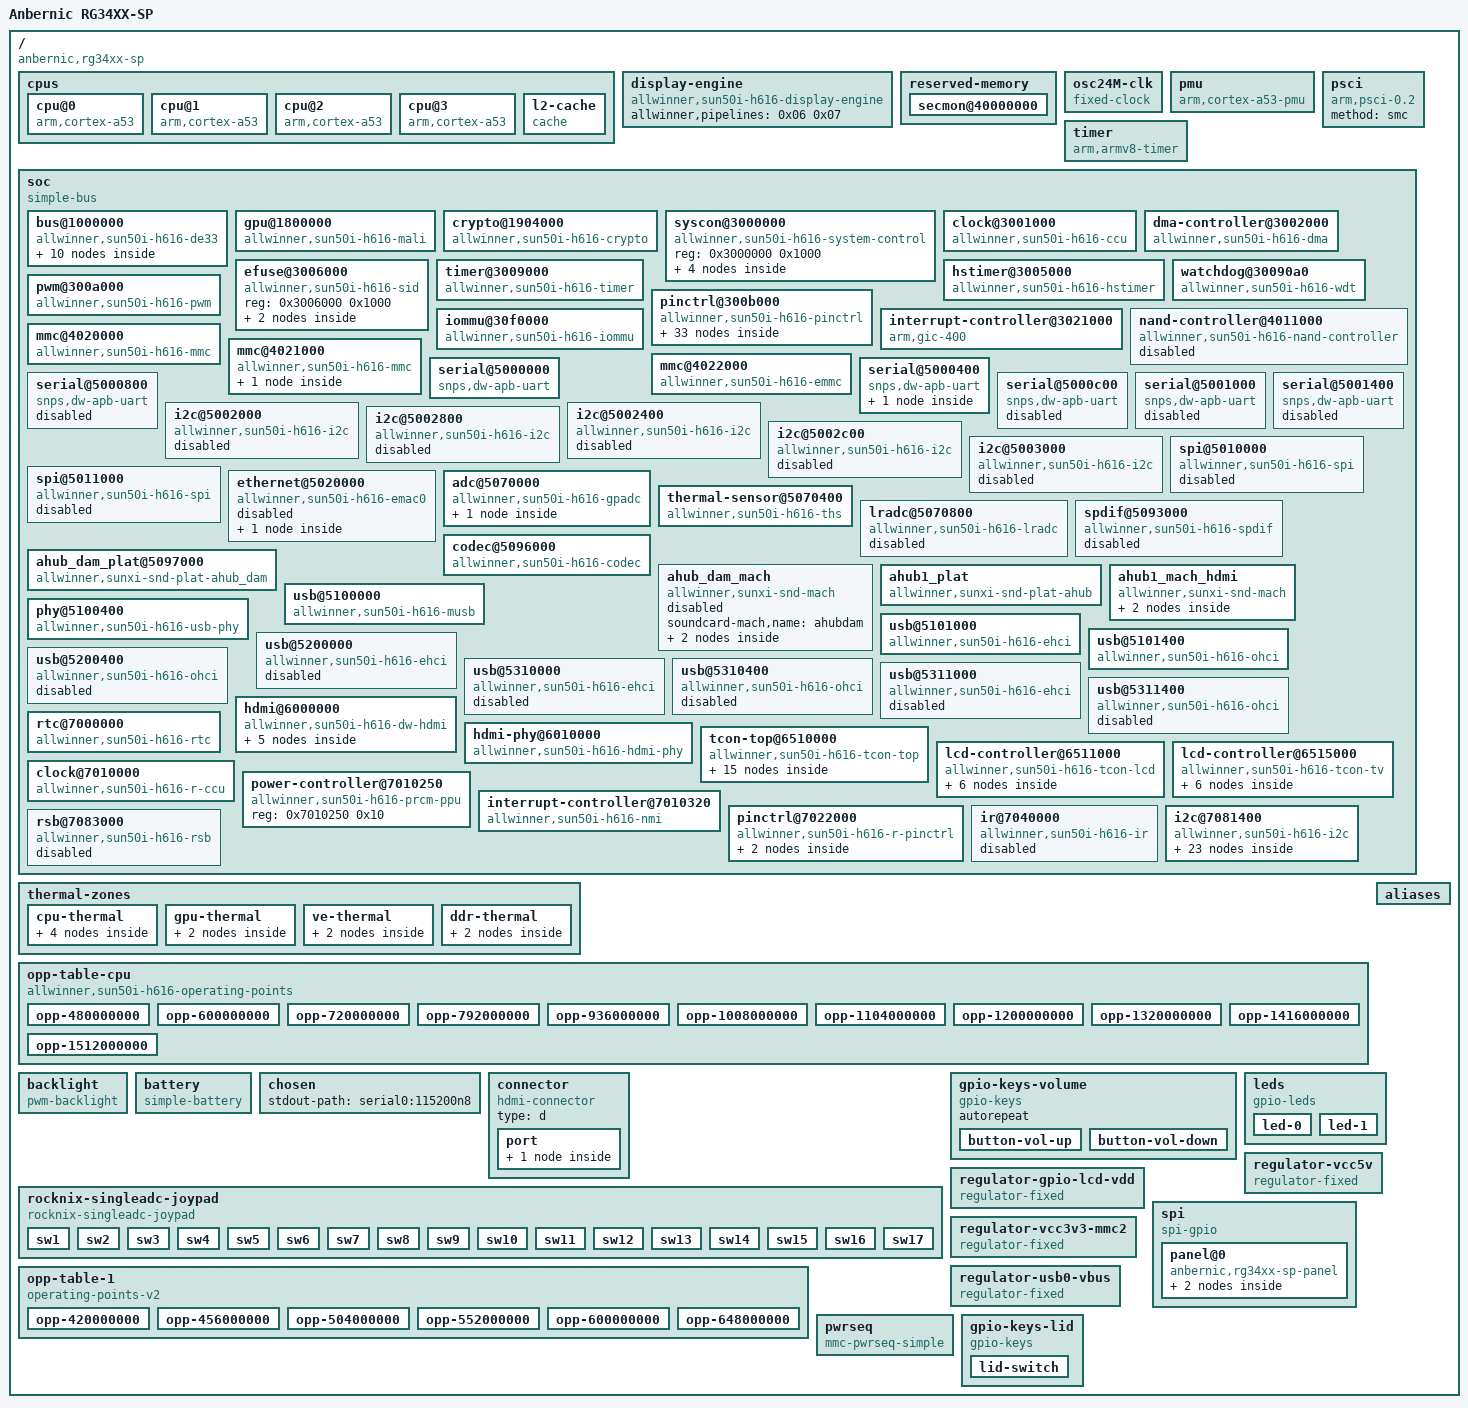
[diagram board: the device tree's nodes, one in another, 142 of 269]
/dts-v1/;

/ {
	interrupt-parent = <0x01>;
	#address-cells = <0x02>;
	#size-cells = <0x02>;
	model = "Anbernic RG34XX-SP";
	chassis-type = "handset";
	compatible = "anbernic,rg34xx-sp\0allwinner,sun50i-h700";
	rocknix-dt-id = "sun50i-h700-anbernic-rg34xx-sp";

	cpus {
		#address-cells = <0x01>;
		#size-cells = <0x00>;

		cpu@0 {
			compatible = "arm,cortex-a53";
			device_type = "cpu";
			reg = <0x00>;
			enable-method = "psci";
			clocks = <0x02 0x15>;
			#cooling-cells = <0x02>;
			i-cache-size = <0x8000>;
			i-cache-line-size = <0x40>;
			i-cache-sets = <0x100>;
			d-cache-size = <0x8000>;
			d-cache-line-size = <0x40>;
			d-cache-sets = <0x80>;
			next-level-cache = <0x03>;
			operating-points-v2 = <0x04>;
			cpu-supply = <0x05>;
			phandle = <0x08>;
		};

		cpu@1 {
			compatible = "arm,cortex-a53";
			device_type = "cpu";
			reg = <0x01>;
			enable-method = "psci";
			clocks = <0x02 0x15>;
			#cooling-cells = <0x02>;
			i-cache-size = <0x8000>;
			i-cache-line-size = <0x40>;
			i-cache-sets = <0x100>;
			d-cache-size = <0x8000>;
			d-cache-line-size = <0x40>;
			d-cache-sets = <0x80>;
			next-level-cache = <0x03>;
			operating-points-v2 = <0x04>;
			phandle = <0x09>;
		};

		cpu@2 {
			compatible = "arm,cortex-a53";
			device_type = "cpu";
			reg = <0x02>;
			enable-method = "psci";
			clocks = <0x02 0x15>;
			#cooling-cells = <0x02>;
			i-cache-size = <0x8000>;
			i-cache-line-size = <0x40>;
			i-cache-sets = <0x100>;
			d-cache-size = <0x8000>;
			d-cache-line-size = <0x40>;
			d-cache-sets = <0x80>;
			next-level-cache = <0x03>;
			operating-points-v2 = <0x04>;
			phandle = <0x0a>;
		};

		cpu@3 {
			compatible = "arm,cortex-a53";
			device_type = "cpu";
			reg = <0x03>;
			enable-method = "psci";
			clocks = <0x02 0x15>;
			#cooling-cells = <0x02>;
			i-cache-size = <0x8000>;
			i-cache-line-size = <0x40>;
			i-cache-sets = <0x100>;
			d-cache-size = <0x8000>;
			d-cache-line-size = <0x40>;
			d-cache-sets = <0x80>;
			next-level-cache = <0x03>;
			operating-points-v2 = <0x04>;
			phandle = <0x0b>;
		};

		l2-cache {
			compatible = "cache";
			cache-level = <0x02>;
			cache-unified;
			cache-size = <0x40000>;
			cache-line-size = <0x40>;
			cache-sets = <0x100>;
			phandle = <0x03>;
		};
	};

	display-engine {
		compatible = "allwinner,sun50i-h616-display-engine";
		allwinner,pipelines = <0x06 0x07>;
		status = "okay";
		phandle = <0x57>;
	};

	reserved-memory {
		#address-cells = <0x02>;
		#size-cells = <0x02>;
		ranges;

		secmon@40000000 {
			reg = <0x00 0x40000000 0x00 0x40000>;
			no-map;
		};
	};

	osc24M-clk {
		#clock-cells = <0x00>;
		compatible = "fixed-clock";
		clock-frequency = <0x16e3600>;
		clock-output-names = "osc24M";
		phandle = <0x15>;
	};

	pmu {
		compatible = "arm,cortex-a53-pmu";
		interrupts = <0x00 0x8c 0x04 0x00 0x8d 0x04 0x00 0x8e 0x04 0x00 0x8f 0x04>;
		interrupt-affinity = <0x08 0x09 0x0a 0x0b>;
	};

	psci {
		compatible = "arm,psci-0.2";
		method = "smc";
	};

	timer {
		compatible = "arm,armv8-timer";
		arm,no-tick-in-suspend;
		interrupts = <0x01 0x0d 0xf04 0x01 0x0e 0xf04 0x01 0x0b 0xf04 0x01 0x0a 0xf04>;
	};

	soc {
		compatible = "simple-bus";
		#address-cells = <0x01>;
		#size-cells = <0x01>;
		ranges = <0x00 0x00 0x00 0x40000000>;

		bus@1000000 {
			compatible = "allwinner,sun50i-h616-de33\0allwinner,sun50i-a64-de2";
			reg = <0x1000000 0x400000>;
			allwinner,sram = <0x0c 0x01>;
			#address-cells = <0x01>;
			#size-cells = <0x01>;
			ranges = <0x00 0x1000000 0x400000>;

			clock@8000 {
				compatible = "allwinner,sun50i-h616-de33-clk";
				reg = <0x8000 0x100>;
				clocks = <0x02 0x1d 0x02 0x1e>;
				clock-names = "mod\0bus";
				resets = <0x02 0x01>;
				#clock-cells = <0x01>;
				#reset-cells = <0x01>;
				phandle = <0x0d>;
			};

			planes@100000 {
				compatible = "allwinner,sun50i-h616-de33-planes";
				reg = <0x100000 0x180000>;
				allwinner,plane-mapping = <0x0d>;
				phandle = <0x0e>;
			};

			mixer@280000 {
				compatible = "allwinner,sun50i-h616-de33-mixer-0";
				reg = <0x280000 0x20000 0x8100 0x40>;
				clocks = <0x0d 0x00 0x0d 0x06>;
				clock-names = "bus\0mod";
				resets = <0x0d 0x00>;
				allwinner,planes = <0x0e>;
				phandle = <0x06>;

				ports {
					#address-cells = <0x01>;
					#size-cells = <0x00>;

					port@1 {
						reg = <0x01>;
						phandle = <0x58>;

						endpoint {
							remote-endpoint = <0x0f>;
							phandle = <0x32>;
						};
					};
				};
			};

			mixer@2a0000 {
				compatible = "allwinner,sun50i-h616-de33-mixer-0";
				reg = <0x2a0000 0x20000 0x8140 0x40>;
				clocks = <0x0d 0x01 0x0d 0x07>;
				clock-names = "bus\0mod";
				resets = <0x0d 0x01>;
				allwinner,planes = <0x0e>;
				phandle = <0x07>;

				ports {
					#address-cells = <0x01>;
					#size-cells = <0x00>;

					port@1 {
						reg = <0x01>;
						phandle = <0x59>;

						endpoint {
							remote-endpoint = <0x10>;
							phandle = <0x35>;
						};
					};
				};
			};
		};

		gpu@1800000 {
			compatible = "allwinner,sun50i-h616-mali\0arm,mali-bifrost";
			reg = <0x1800000 0x40000>;
			interrupts = <0x00 0x5f 0x04 0x00 0x60 0x04 0x00 0x61 0x04>;
			interrupt-names = "job\0mmu\0gpu";
			clocks = <0x02 0x23 0x02 0x24>;
			clock-names = "core\0bus";
			power-domains = <0x11 0x02>;
			resets = <0x02 0x03>;
			status = "okay";
			mali-supply = <0x12>;
			operating-points-v2 = <0x13>;
			phandle = <0x5a>;
		};

		crypto@1904000 {
			compatible = "allwinner,sun50i-h616-crypto";
			reg = <0x1904000 0x800>;
			interrupts = <0x00 0x5b 0x04>;
			clocks = <0x02 0x27 0x02 0x26 0x02 0x34 0x14 0x02>;
			clock-names = "bus\0mod\0ram\0trng";
			resets = <0x02 0x04>;
			phandle = <0x5b>;
		};

		syscon@3000000 {
			compatible = "allwinner,sun50i-h616-system-control";
			reg = <0x3000000 0x1000>;
			#address-cells = <0x01>;
			#size-cells = <0x01>;
			ranges;
			phandle = <0x24>;

			sram@28000 {
				compatible = "mmio-sram";
				reg = <0x28000 0x30000>;
				#address-cells = <0x01>;
				#size-cells = <0x01>;
				ranges = <0x00 0x28000 0x30000>;

				sram-section@0 {
					compatible = "allwinner,sun50i-h616-sram-c\0allwinner,sun50i-a64-sram-c";
					reg = <0x00 0x30000>;
					phandle = <0x0c>;
				};
			};

			sram@1a00000 {
				compatible = "mmio-sram";
				reg = <0x1a00000 0x200000>;
				#address-cells = <0x01>;
				#size-cells = <0x01>;
				ranges = <0x00 0x1a00000 0x200000>;

				sram-section@0 {
					compatible = "allwinner,sun50i-h616-ve-sram";
					reg = <0x00 0x200000>;
					phandle = <0x5c>;
				};
			};
		};

		clock@3001000 {
			compatible = "allwinner,sun50i-h616-ccu";
			reg = <0x3001000 0x1000>;
			clocks = <0x15 0x14 0x00 0x14 0x02>;
			clock-names = "hosc\0losc\0iosc";
			#clock-cells = <0x01>;
			#reset-cells = <0x01>;
			phandle = <0x02>;
		};

		dma-controller@3002000 {
			compatible = "allwinner,sun50i-h616-dma\0allwinner,sun50i-a100-dma";
			reg = <0x3002000 0x1000>;
			interrupts = <0x00 0x2a 0x04>;
			clocks = <0x02 0x2a 0x02 0x32>;
			clock-names = "bus\0mbus";
			dma-channels = <0x10>;
			dma-requests = <0x31>;
			resets = <0x02 0x06>;
			#dma-cells = <0x01>;
			phandle = <0x18>;
		};

		efuse@3006000 {
			compatible = "allwinner,sun50i-h616-sid\0allwinner,sun50i-a64-sid";
			reg = <0x3006000 0x1000>;
			#address-cells = <0x01>;
			#size-cells = <0x01>;
			phandle = <0x5d>;

			thermal-sensor-calibration@14 {
				reg = <0x14 0x08>;
				phandle = <0x25>;
			};

			cpu-speed-grade@0 {
				reg = <0x00 0x02>;
				phandle = <0x49>;
			};
		};

		timer@3009000 {
			compatible = "allwinner,sun50i-h616-timer\0allwinner,sun8i-a23-timer";
			reg = <0x3009000 0xa0>;
			interrupts = <0x00 0x30 0x04 0x00 0x31 0x04>;
			clocks = <0x15>;
			phandle = <0x5e>;
		};

		hstimer@3005000 {
			compatible = "allwinner,sun50i-h616-hstimer\0allwinner,sun20i-d1-hstimer";
			reg = <0x3005000 0x1000>;
			interrupts = <0x00 0x2d 0x04 0x00 0x2e 0x04>;
			clocks = <0x02 0x2b>;
			resets = <0x02 0x07>;
		};

		watchdog@30090a0 {
			compatible = "allwinner,sun50i-h616-wdt\0allwinner,sun6i-a31-wdt";
			reg = <0x30090a0 0x20>;
			interrupts = <0x00 0x32 0x04>;
			clocks = <0x15>;
			phandle = <0x5f>;
		};

		pwm@300a000 {
			compatible = "allwinner,sun50i-h616-pwm";
			reg = <0x300a000 0x400>;
			clocks = <0x15 0x02 0x2f>;
			clock-names = "mod\0bus";
			resets = <0x02 0x0a>;
			#pwm-cells = <0x03>;
			#clock-cells = <0x01>;
			status = "okay";
			phandle = <0x4a>;
		};

		pinctrl@300b000 {
			compatible = "allwinner,sun50i-h616-pinctrl";
			reg = <0x300b000 0x400>;
			interrupts = <0x00 0x33 0x04 0x00 0x34 0x04 0x00 0x35 0x04 0x00 0x2b 0x04 0x00 0x36 0x04 0x00 0x37 0x04 0x00 0x38 0x04 0x00 0x39 0x04>;
			clocks = <0x02 0x1a 0x15 0x14 0x00>;
			clock-names = "apb\0hosc\0losc";
			gpio-controller;
			#gpio-cells = <0x03>;
			interrupt-controller;
			#interrupt-cells = <0x03>;
			vcc-pa-supply = <0x16>;
			vcc-pc-supply = <0x16>;
			vcc-pd-supply = <0x16>;
			vcc-pe-supply = <0x16>;
			vcc-pf-supply = <0x16>;
			vcc-pg-supply = <0x17>;
			vcc-ph-supply = <0x16>;
			vcc-pi-supply = <0x16>;
			phandle = <0x1a>;

			rgmii-pins {
				pins = "PI0\0PI1\0PI2\0PI3\0PI4\0PI5\0PI7\0PI8\0PI9\0PI10\0PI11\0PI12\0PI13\0PI14\0PI15\0PI16";
				function = "emac0";
				drive-strength = <0x28>;
				phandle = <0x60>;
			};

			i2c0-pins {
				pins = "PI5\0PI6";
				function = "i2c0";
				phandle = <0x23>;
			};

			i2c3-ph-pins {
				pins = "PH4\0PH5";
				function = "i2c3";
				phandle = <0x61>;
			};

			ir-rx-pin {
				pins = "PH10";
				function = "ir_rx";
				phandle = <0x42>;
			};

			lcd0-rgb888-pins {
				pins = "PD0\0PD1\0PD2\0PD3\0PD4\0PD5\0PD6\0PD7\0PD8\0PD9\0PD10\0PD11\0PD12\0PD13\0PD14\0PD15\0PD16\0PD17\0PD18\0PD19\0PD20\0PD21\0PD22\0PD23\0PD24\0PD25\0PD26\0PD27";
				function = "lcd0";
				phandle = <0x52>;
			};

			lcd0-suspend-pins {
				pins = "PD0\0PD1\0PD2\0PD3\0PD4\0PD5\0PD6\0PD7\0PD8\0PD9\0PD10\0PD11\0PD12\0PD13\0PD14\0PD15\0PD16\0PD17\0PD18\0PD19\0PD20\0PD21\0PD22\0PD23\0PD24\0PD25\0PD26\0PD27";
				function = "io_disabled";
				bias-disable;
				phandle = <0x53>;
			};

			lvds0-pins {
				pins = "PD0\0PD1\0PD2\0PD3\0PD4\0PD5\0PD6\0PD7\0PD8\0PD9";
				function = "lvds0";
				phandle = <0x62>;
			};

			lvds1-pins {
				pins = "PD10\0PD11\0PD12\0PD13\0PD14\0PD15\0PD16\0PD17\0PD18\0PD19";
				function = "lvds1";
				phandle = <0x63>;
			};

			mmc0-pins {
				pins = "PF0\0PF1\0PF2\0PF3\0PF4\0PF5";
				function = "mmc0";
				drive-strength = <0x1e>;
				bias-pull-up;
				phandle = <0x19>;
			};

			mmc1-pins {
				pins = "PG0\0PG1\0PG2\0PG3\0PG4\0PG5";
				function = "mmc1";
				drive-strength = <0x1e>;
				bias-pull-up;
				phandle = <0x1b>;
			};

			mmc2-pins {
				pins = "PC0\0PC1\0PC5\0PC6\0PC8\0PC9\0PC10\0PC11\0PC13\0PC14\0PC15\0PC16";
				function = "mmc2";
				drive-strength = <0x1e>;
				bias-pull-up;
				phandle = <0x1e>;
			};

			nand-pins {
				pins = "PC0\0PC1\0PC2\0PC5\0PC8\0PC9\0PC10\0PC11\0PC12\0PC13\0PC14\0PC15\0PC16";
				function = "nand0";
				phandle = <0x64>;
			};

			nand-cs0-pin {
				pins = "PC4";
				function = "nand0";
				bias-pull-up;
				phandle = <0x65>;
			};

			nand-cs1-pin {
				pins = "PC3";
				function = "nand0";
				bias-pull-up;
				phandle = <0x66>;
			};

			nand-rb0-pin {
				pins = "PC6";
				function = "nand0";
				bias-pull-up;
				phandle = <0x67>;
			};

			nand-rb1-pin {
				pins = "PC7";
				function = "nand0";
				bias-pull-up;
				phandle = <0x68>;
			};

			pwm0-pin {
				pins = "PD28";
				function = "pwm0";
				phandle = <0x4b>;
			};

			pwm1-pin {
				pins = "PG19";
				function = "pwm1";
				phandle = <0x69>;
			};

			pwm2-pin {
				pins = "PH2";
				function = "pwm2";
				phandle = <0x4e>;
			};

			pwm3-pin {
				pins = "PI13";
				function = "pwm3";
				phandle = <0x6a>;
			};

			pwm4-pin {
				pins = "PI14";
				function = "pwm4";
				phandle = <0x6b>;
			};

			pwm5-pin {
				pins = "PA12";
				function = "pwm5";
				phandle = <0x6c>;
			};

			spi0-pins {
				pins = "PC0\0PC2\0PC4";
				function = "spi0";
				phandle = <0x6d>;
			};

			spi0-cs0-pin {
				pins = "PC3";
				function = "spi0";
				phandle = <0x6e>;
			};

			spi1-pins {
				pins = "PH6\0PH7\0PH8";
				function = "spi1";
				phandle = <0x6f>;
			};

			spi1-cs0-pin {
				pins = "PH5";
				function = "spi1";
				phandle = <0x70>;
			};

			spdif-tx-pin {
				pins = "PH4";
				function = "spdif";
				phandle = <0x26>;
			};

			uart0-ph-pins {
				pins = "PH0\0PH1";
				function = "uart0";
				phandle = <0x20>;
			};

			uart1-pins {
				pins = "PG6\0PG7";
				function = "uart1";
				phandle = <0x21>;
			};

			uart1-rts-cts-pins {
				pins = "PG8\0PG9";
				function = "uart1";
				phandle = <0x22>;
			};

			x32clk-fanout-pin {
				pins = "PG10";
				function = "clock";
				phandle = <0x56>;
			};

			joy-mux-pin {
				pins = "PI0";
				function = "gpio_out";
				phandle = <0x4d>;
			};

			uart5-ph-pins {
				pins = "PH2\0PH3";
				function = "uart5";
				phandle = <0x71>;
			};
		};

		interrupt-controller@3021000 {
			compatible = "arm,gic-400";
			reg = <0x3021000 0x1000 0x3022000 0x2000 0x3024000 0x2000 0x3026000 0x2000>;
			interrupts = <0x01 0x09 0xf04>;
			interrupt-controller;
			#interrupt-cells = <0x03>;
			phandle = <0x01>;
		};

		iommu@30f0000 {
			compatible = "allwinner,sun50i-h616-iommu";
			reg = <0x30f0000 0x10000>;
			interrupts = <0x00 0x3d 0x04>;
			clocks = <0x02 0x30>;
			resets = <0x02 0x0b>;
			#iommu-cells = <0x01>;
			phandle = <0x72>;
		};

		nand-controller@4011000 {
			compatible = "allwinner,sun50i-h616-nand-controller";
			reg = <0x4011000 0x1000>;
			interrupts = <0x00 0x22 0x04>;
			clocks = <0x02 0x3b 0x02 0x39 0x02 0x3a 0x02 0x36>;
			clock-names = "ahb\0mod\0ecc\0mbus";
			resets = <0x02 0x0d>;
			reset-names = "ahb";
			dmas = <0x18 0x0a>;
			dma-names = "rxtx";
			#address-cells = <0x01>;
			#size-cells = <0x00>;
			status = "disabled";
			phandle = <0x73>;
		};

		mmc@4020000 {
			compatible = "allwinner,sun50i-h616-mmc\0allwinner,sun50i-a100-mmc";
			reg = <0x4020000 0x1000>;
			clocks = <0x02 0x3f 0x02 0x3c>;
			clock-names = "ahb\0mmc";
			resets = <0x02 0x0e>;
			reset-names = "ahb";
			interrupts = <0x00 0x23 0x04>;
			pinctrl-names = "default";
			pinctrl-0 = <0x19>;
			status = "okay";
			max-frequency = <0x8f0d180>;
			cap-sd-highspeed;
			cap-mmc-highspeed;
			mmc-ddr-3_3v;
			cap-sdio-irq;
			#address-cells = <0x01>;
			#size-cells = <0x00>;
			bus-width = <0x04>;
			cd-gpios = <0x1a 0x05 0x06 0x01>;
			disable-wp;
			no-1-8-v;
			vmmc-supply = <0x16>;
			phandle = <0x74>;
		};

		mmc@4021000 {
			compatible = "allwinner,sun50i-h616-mmc\0allwinner,sun50i-a100-mmc";
			reg = <0x4021000 0x1000>;
			clocks = <0x02 0x40 0x02 0x3d>;
			clock-names = "ahb\0mmc";
			resets = <0x02 0x0f>;
			reset-names = "ahb";
			interrupts = <0x00 0x24 0x04>;
			pinctrl-names = "default";
			pinctrl-0 = <0x1b>;
			status = "okay";
			max-frequency = <0x8f0d180>;
			cap-sd-highspeed;
			cap-mmc-highspeed;
			mmc-ddr-3_3v;
			cap-sdio-irq;
			#address-cells = <0x01>;
			#size-cells = <0x00>;
			vmmc-supply = <0x1c>;
			vqmmc-supply = <0x17>;
			keep-power-in-suspend;
			bus-width = <0x04>;
			non-removable;
			mmc-pwrseq = <0x1d>;
			phandle = <0x75>;

			wifi@1 {
				reg = <0x01>;
				interrupt-parent = <0x1a>;
				interrupts = <0x06 0x0f 0x08>;
				interrupt-names = "host-wake";
				phandle = <0x76>;
			};
		};

		mmc@4022000 {
			compatible = "allwinner,sun50i-h616-emmc\0allwinner,sun50i-a100-emmc";
			reg = <0x4022000 0x1000>;
			clocks = <0x02 0x41 0x02 0x3e>;
			clock-names = "ahb\0mmc";
			resets = <0x02 0x10>;
			reset-names = "ahb";
			interrupts = <0x00 0x25 0x04>;
			pinctrl-names = "default";
			pinctrl-0 = <0x1e>;
			status = "okay";
			max-frequency = <0x8f0d180>;
			cap-sd-highspeed;
			cap-mmc-highspeed;
			mmc-ddr-3_3v;
			cap-sdio-irq;
			#address-cells = <0x01>;
			#size-cells = <0x00>;
			bus-width = <0x04>;
			cd-gpios = <0x1a 0x04 0x16 0x01>;
			disable-wp;
			no-1-8-v;
			vmmc-supply = <0x1f>;
			vqmmc-supply = <0x16>;
			phandle = <0x77>;
		};

		serial@5000000 {
			compatible = "snps,dw-apb-uart";
			reg = <0x5000000 0x400>;
			interrupts = <0x00 0x00 0x04>;
			reg-shift = <0x02>;
			reg-io-width = <0x04>;
			clocks = <0x02 0x42>;
			dmas = <0x18 0x0e 0x18 0x0e>;
			dma-names = "tx\0rx";
			resets = <0x02 0x11>;
			status = "okay";
			pinctrl-names = "default";
			pinctrl-0 = <0x20>;
			phandle = <0x78>;
		};

		serial@5000400 {
			compatible = "snps,dw-apb-uart";
			reg = <0x5000400 0x400>;
			interrupts = <0x00 0x01 0x04>;
			reg-shift = <0x02>;
			reg-io-width = <0x04>;
			clocks = <0x02 0x43>;
			dmas = <0x18 0x0f 0x18 0x0f>;
			dma-names = "tx\0rx";
			resets = <0x02 0x12>;
			status = "okay";
			pinctrl-names = "default";
			pinctrl-0 = <0x21 0x22>;
			uart-has-rtscts;
			phandle = <0x79>;

			bluetooth {
				compatible = "realtek,rtl8821cs-bt\0realtek,rtl8723bs-bt";
				device-wake-gpios = <0x1a 0x06 0x11 0x00>;
				enable-gpios = <0x1a 0x06 0x13 0x00>;
				host-wake-gpios = <0x1a 0x06 0x10 0x00>;
			};
		};

		serial@5000800 {
			compatible = "snps,dw-apb-uart";
			reg = <0x5000800 0x400>;
			interrupts = <0x00 0x02 0x04>;
			reg-shift = <0x02>;
			reg-io-width = <0x04>;
			clocks = <0x02 0x44>;
			dmas = <0x18 0x10 0x18 0x10>;
			dma-names = "tx\0rx";
			resets = <0x02 0x13>;
			status = "disabled";
			phandle = <0x7a>;
		};

		serial@5000c00 {
			compatible = "snps,dw-apb-uart";
			reg = <0x5000c00 0x400>;
			interrupts = <0x00 0x03 0x04>;
			reg-shift = <0x02>;
			reg-io-width = <0x04>;
			clocks = <0x02 0x45>;
			dmas = <0x18 0x11 0x18 0x11>;
			dma-names = "tx\0rx";
			resets = <0x02 0x14>;
			status = "disabled";
			phandle = <0x7b>;
		};

		serial@5001000 {
			compatible = "snps,dw-apb-uart";
			reg = <0x5001000 0x400>;
			interrupts = <0x00 0x04 0x04>;
			reg-shift = <0x02>;
			reg-io-width = <0x04>;
			clocks = <0x02 0x46>;
			dmas = <0x18 0x12 0x18 0x12>;
			dma-names = "tx\0rx";
			resets = <0x02 0x15>;
			status = "disabled";
			phandle = <0x7c>;
		};

		serial@5001400 {
			compatible = "snps,dw-apb-uart";
			reg = <0x5001400 0x400>;
			interrupts = <0x00 0x05 0x04>;
			reg-shift = <0x02>;
			reg-io-width = <0x04>;
			clocks = <0x02 0x47>;
			dmas = <0x18 0x13 0x18 0x13>;
			dma-names = "tx\0rx";
			resets = <0x02 0x16>;
			status = "disabled";
			phandle = <0x7d>;
		};

		i2c@5002000 {
			compatible = "allwinner,sun50i-h616-i2c\0allwinner,sun8i-v536-i2c\0allwinner,sun6i-a31-i2c";
			reg = <0x5002000 0x400>;
			interrupts = <0x00 0x06 0x04>;
			clocks = <0x02 0x48>;
			dmas = <0x18 0x2b 0x18 0x2b>;
			dma-names = "rx\0tx";
			resets = <0x02 0x17>;
			pinctrl-names = "default";
			pinctrl-0 = <0x23>;
			status = "disabled";
			#address-cells = <0x01>;
			#size-cells = <0x00>;
			phandle = <0x7e>;
		};

		i2c@5002400 {
			compatible = "allwinner,sun50i-h616-i2c\0allwinner,sun8i-v536-i2c\0allwinner,sun6i-a31-i2c";
			reg = <0x5002400 0x400>;
			interrupts = <0x00 0x07 0x04>;
			clocks = <0x02 0x49>;
			dmas = <0x18 0x2c 0x18 0x2c>;
			dma-names = "rx\0tx";
			resets = <0x02 0x18>;
			status = "disabled";
			#address-cells = <0x01>;
			#size-cells = <0x00>;
			phandle = <0x7f>;
		};

		i2c@5002800 {
			compatible = "allwinner,sun50i-h616-i2c\0allwinner,sun8i-v536-i2c\0allwinner,sun6i-a31-i2c";
			reg = <0x5002800 0x400>;
			interrupts = <0x00 0x08 0x04>;
			clocks = <0x02 0x4a>;
			dmas = <0x18 0x2d 0x18 0x2d>;
			dma-names = "rx\0tx";
			resets = <0x02 0x19>;
			status = "disabled";
			#address-cells = <0x01>;
			#size-cells = <0x00>;
			phandle = <0x80>;
		};

		i2c@5002c00 {
			compatible = "allwinner,sun50i-h616-i2c\0allwinner,sun8i-v536-i2c\0allwinner,sun6i-a31-i2c";
			reg = <0x5002c00 0x400>;
			interrupts = <0x00 0x09 0x04>;
			clocks = <0x02 0x4b>;
			dmas = <0x18 0x2e 0x18 0x2e>;
			dma-names = "rx\0tx";
			resets = <0x02 0x1a>;
			status = "disabled";
			#address-cells = <0x01>;
			#size-cells = <0x00>;
			phandle = <0x81>;
		};

		i2c@5003000 {
			compatible = "allwinner,sun50i-h616-i2c\0allwinner,sun8i-v536-i2c\0allwinner,sun6i-a31-i2c";
			reg = <0x5003000 0x400>;
			interrupts = <0x00 0x0a 0x04>;
			clocks = <0x02 0x4c>;
			dmas = <0x18 0x2f 0x18 0x2f>;
			dma-names = "rx\0tx";
			resets = <0x02 0x1b>;
			status = "disabled";
			#address-cells = <0x01>;
			#size-cells = <0x00>;
			phandle = <0x82>;
		};

		spi@5010000 {
			compatible = "allwinner,sun50i-h616-spi\0allwinner,sun8i-h3-spi";
			reg = <0x5010000 0x1000>;
			interrupts = <0x00 0x0c 0x04>;
			clocks = <0x02 0x4f 0x02 0x4d>;
			clock-names = "ahb\0mod";
			dmas = <0x18 0x16 0x18 0x16>;
			dma-names = "rx\0tx";
			resets = <0x02 0x1c>;
			status = "disabled";
			#address-cells = <0x01>;
			#size-cells = <0x00>;
			phandle = <0x83>;
		};

		spi@5011000 {
			compatible = "allwinner,sun50i-h616-spi\0allwinner,sun8i-h3-spi";
			reg = <0x5011000 0x1000>;
			interrupts = <0x00 0x0d 0x04>;
			clocks = <0x02 0x50 0x02 0x4e>;
			clock-names = "ahb\0mod";
			dmas = <0x18 0x17 0x18 0x17>;
			dma-names = "rx\0tx";
			resets = <0x02 0x1d>;
			status = "disabled";
			#address-cells = <0x01>;
			#size-cells = <0x00>;
			phandle = <0x84>;
		};

		ethernet@5020000 {
			compatible = "allwinner,sun50i-h616-emac0\0allwinner,sun50i-a64-emac";
			reg = <0x5020000 0x10000>;
			interrupts = <0x00 0x0e 0x04>;
			interrupt-names = "macirq";
			clocks = <0x02 0x52>;
			clock-names = "stmmaceth";
			resets = <0x02 0x1e>;
			reset-names = "stmmaceth";
			syscon = <0x24>;
			status = "disabled";
			phandle = <0x85>;

			mdio {
				compatible = "snps,dwmac-mdio";
				#address-cells = <0x01>;
				#size-cells = <0x00>;
				phandle = <0x86>;
			};
		};

		adc@5070000 {
			compatible = "allwinner,sun50i-h616-gpadc\0allwinner,sun20i-d1-gpadc";
			reg = <0x5070000 0x400>;
			clocks = <0x02 0x81>;
			resets = <0x02 0x3c>;
			interrupts = <0x00 0x12 0x04>;
			status = "okay";
			#io-channel-cells = <0x01>;
			#address-cells = <0x01>;
			#size-cells = <0x00>;
			phandle = <0x4f>;

			channel@0 {
				reg = <0x00>;
			};
		};

		thermal-sensor@5070400 {
			compatible = "allwinner,sun50i-h616-ths";
			reg = <0x5070400 0x400>;
			interrupts = <0x00 0x13 0x04>;
			clocks = <0x02 0x56>;
			clock-names = "bus";
			resets = <0x02 0x21>;
			nvmem-cells = <0x25>;
			nvmem-cell-names = "calibration";
			allwinner,sram = <0x24>;
			#thermal-sensor-cells = <0x01>;
			phandle = <0x48>;
		};

		lradc@5070800 {
			compatible = "allwinner,sun50i-h616-lradc\0allwinner,sun50i-r329-lradc";
			reg = <0x5070800 0x400>;
			interrupts = <0x00 0x14 0x04>;
			clocks = <0x02 0x71>;
			resets = <0x02 0x3b>;
			status = "disabled";
			phandle = <0x87>;
		};

		spdif@5093000 {
			compatible = "allwinner,sun50i-h616-spdif";
			reg = <0x5093000 0x400>;
			interrupts = <0x00 0x15 0x04>;
			clocks = <0x02 0x58 0x02 0x57>;
			clock-names = "apb\0spdif";
			resets = <0x02 0x22>;
			dmas = <0x18 0x02>;
			dma-names = "tx";
			pinctrl-names = "default";
			pinctrl-0 = <0x26>;
			#sound-dai-cells = <0x00>;
			status = "disabled";
			phandle = <0x88>;
		};

		codec@5096000 {
			#sound-dai-cells = <0x00>;
			compatible = "allwinner,sun50i-h616-codec";
			reg = <0x5096000 0x31c>;
			interrupts = <0x00 0x3a 0x04>;
			clocks = <0x02 0x5d 0x02 0x5b>;
			clock-names = "apb\0codec";
			resets = <0x02 0x24>;
			dmas = <0x18 0x06>;
			dma-names = "tx";
			status = "okay";
			allwinner,audio-routing = "Speaker\0LINEOUT\0Headphone\0LINEOUT";
			allwinner,pa-gpios = <0x1a 0x08 0x05 0x00>;
			allwinner,pa-supply = <0x27>;
			hp-det-gpios = <0x1a 0x08 0x03 0x00>;
			phandle = <0x89>;
		};

		ahub_dam_plat@5097000 {
			#sound-dai-cells = <0x00>;
			compatible = "allwinner,sunxi-snd-plat-ahub_dam";
			reg = <0x5097000 0x1000>;
			resets = <0x02 0x25>;
			clocks = <0x02 0x5b 0x02 0x5c 0x02 0x5e 0x02 0x5f>;
			clock-names = "clk_pll_audio\0clk_pll_audio_4x\0clk_audio_hub\0clk_bus_audio_hub";
			status = "okay";
			phandle = <0x28>;
		};

		ahub_dam_mach {
			compatible = "allwinner,sunxi-snd-mach";
			soundcard-mach,name = "ahubdam";
			status = "disabled";
			phandle = <0x8a>;

			soundcard-mach,cpu {
				sound-dai = <0x28>;
			};

			soundcard-mach,codec {
			};
		};

		ahub1_plat {
			#sound-dai-cells = <0x00>;
			compatible = "allwinner,sunxi-snd-plat-ahub";
			apb_num = <0x01>;
			dmas = <0x18 0x04 0x18 0x04>;
			dma-names = "tx\0rx";
			playback_cma = <0x80>;
			capture_cma = <0x80>;
			tx_fifo_size = <0x80>;
			rx_fifo_size = <0x80>;
			tdm_num = <0x01>;
			tx_pin = <0x00>;
			rx_pin = <0x00>;
			status = "okay";
			phandle = <0x2a>;
		};

		ahub1_mach_hdmi {
			compatible = "allwinner,sunxi-snd-mach";
			soundcard-mach,name = "HDMI";
			soundcard-mach,format = "i2s";
			soundcard-mach,frame-master = <0x29>;
			soundcard-mach,bitclock-master = <0x29>;
			soundcard-mach,slot-num = <0x02>;
			soundcard-mach,slot-width = <0x20>;
			status = "okay";
			phandle = <0x8b>;

			soundcard-mach,cpu {
				sound-dai = <0x2a>;
				soundcard-mach,pll-fs = <0x04>;
				soundcard-mach,mclk-fs = <0x00>;
				phandle = <0x29>;
			};

			soundcard-mach,codec {
				sound-dai = <0x2b>;
				phandle = <0x8c>;
			};
		};

		usb@5100000 {
			compatible = "allwinner,sun50i-h616-musb\0allwinner,sun8i-h3-musb";
			reg = <0x5100000 0x400>;
			clocks = <0x02 0x70>;
			resets = <0x02 0x32>;
			interrupts = <0x00 0x19 0x04>;
			interrupt-names = "mc";
			phys = <0x2c 0x00>;
			phy-names = "usb";
			extcon = <0x2c 0x00>;
			status = "okay";
			dr_mode = "otg";
			phandle = <0x8d>;
		};

		phy@5100400 {
			compatible = "allwinner,sun50i-h616-usb-phy";
			reg = <0x5100400 0x24 0x5101800 0x14 0x5200800 0x14 0x5310800 0x14 0x5311800 0x14>;
			reg-names = "phy_ctrl\0pmu0\0pmu1\0pmu2\0pmu3";
			clocks = <0x02 0x61 0x02 0x63 0x02 0x65 0x02 0x67 0x02 0x6e>;
			clock-names = "usb0_phy\0usb1_phy\0usb2_phy\0usb3_phy\0pmu2_clk";
			resets = <0x02 0x26 0x02 0x27 0x02 0x28 0x02 0x29>;
			reset-names = "usb0_reset\0usb1_reset\0usb2_reset\0usb3_reset";
			status = "okay";
			#phy-cells = <0x01>;
			usb0_id_det-gpios = <0x1a 0x08 0x04 0x11>;
			usb0_vbus_power-supply = <0x2d>;
			usb0_vbus-supply = <0x2e>;
			phandle = <0x2c>;
		};

		usb@5101000 {
			compatible = "allwinner,sun50i-h616-ehci\0generic-ehci";
			reg = <0x5101000 0x100>;
			interrupts = <0x00 0x1a 0x04>;
			clocks = <0x02 0x68 0x02 0x6c 0x02 0x60>;
			resets = <0x02 0x2a 0x02 0x2e>;
			phys = <0x2c 0x00>;
			phy-names = "usb";
			status = "okay";
			phandle = <0x8e>;
		};

		usb@5101400 {
			compatible = "allwinner,sun50i-h616-ohci\0generic-ohci";
			reg = <0x5101400 0x100>;
			interrupts = <0x00 0x1b 0x04>;
			clocks = <0x02 0x68 0x02 0x60>;
			resets = <0x02 0x2a>;
			phys = <0x2c 0x00>;
			phy-names = "usb";
			status = "okay";
			phandle = <0x8f>;
		};

		usb@5200000 {
			compatible = "allwinner,sun50i-h616-ehci\0generic-ehci";
			reg = <0x5200000 0x100>;
			interrupts = <0x00 0x1c 0x04>;
			clocks = <0x02 0x69 0x02 0x6d 0x02 0x62>;
			resets = <0x02 0x2b 0x02 0x2f>;
			phys = <0x2c 0x01>;
			phy-names = "usb";
			status = "disabled";
			phandle = <0x90>;
		};

		usb@5200400 {
			compatible = "allwinner,sun50i-h616-ohci\0generic-ohci";
			reg = <0x5200400 0x100>;
			interrupts = <0x00 0x1d 0x04>;
			clocks = <0x02 0x69 0x02 0x62>;
			resets = <0x02 0x2b>;
			phys = <0x2c 0x01>;
			phy-names = "usb";
			status = "disabled";
			phandle = <0x91>;
		};

		usb@5310000 {
			compatible = "allwinner,sun50i-h616-ehci\0generic-ehci";
			reg = <0x5310000 0x100>;
			interrupts = <0x00 0x1e 0x04>;
			clocks = <0x02 0x6a 0x02 0x6e 0x02 0x64>;
			resets = <0x02 0x2c 0x02 0x30>;
			phys = <0x2c 0x02>;
			phy-names = "usb";
			status = "disabled";
			phandle = <0x92>;
		};

		usb@5310400 {
			compatible = "allwinner,sun50i-h616-ohci\0generic-ohci";
			reg = <0x5310400 0x100>;
			interrupts = <0x00 0x1f 0x04>;
			clocks = <0x02 0x6a 0x02 0x64>;
			resets = <0x02 0x2c>;
			phys = <0x2c 0x02>;
			phy-names = "usb";
			status = "disabled";
			phandle = <0x93>;
		};

		usb@5311000 {
			compatible = "allwinner,sun50i-h616-ehci\0generic-ehci";
			reg = <0x5311000 0x100>;
			interrupts = <0x00 0x20 0x04>;
			clocks = <0x02 0x6b 0x02 0x6f 0x02 0x66>;
			resets = <0x02 0x2d 0x02 0x31>;
			phys = <0x2c 0x03>;
			phy-names = "usb";
			status = "disabled";
			phandle = <0x94>;
		};

		usb@5311400 {
			compatible = "allwinner,sun50i-h616-ohci\0generic-ohci";
			reg = <0x5311400 0x100>;
			interrupts = <0x00 0x21 0x04>;
			clocks = <0x02 0x6b 0x02 0x66>;
			resets = <0x02 0x2d>;
			phys = <0x2c 0x03>;
			phy-names = "usb";
			status = "disabled";
			phandle = <0x95>;
		};

		hdmi@6000000 {
			compatible = "allwinner,sun50i-h616-dw-hdmi\0allwinner,sun50i-h6-dw-hdmi";
			#sound-dai-cells = <0x00>;
			reg = <0x6000000 0x10000>;
			reg-io-width = <0x01>;
			interrupts = <0x00 0x3f 0x04>;
			clocks = <0x02 0x75 0x02 0x73 0x02 0x72 0x02 0x74 0x02 0x7e 0x02 0x7f>;
			clock-names = "iahb\0isfr\0tmds\0cec\0hdcp\0hdcp-bus";
			resets = <0x02 0x33 0x02 0x3a>;
			reset-names = "ctrl\0hdcp";
			phys = <0x2f>;
			phy-names = "phy";
			status = "okay";
			phandle = <0x2b>;

			ports {
				#address-cells = <0x01>;
				#size-cells = <0x00>;

				port@0 {
					reg = <0x00>;
					phandle = <0x96>;

					endpoint {
						remote-endpoint = <0x30>;
						phandle = <0x39>;
					};
				};

				port@1 {
					reg = <0x01>;
					phandle = <0x97>;

					endpoint {
						remote-endpoint = <0x31>;
						phandle = <0x4c>;
					};
				};
			};
		};

		hdmi-phy@6010000 {
			compatible = "allwinner,sun50i-h616-hdmi-phy";
			reg = <0x6010000 0x10000>;
			clocks = <0x02 0x75 0x02 0x73>;
			clock-names = "bus\0mod";
			resets = <0x02 0x34>;
			reset-names = "phy";
			#phy-cells = <0x00>;
			phandle = <0x2f>;
		};

		tcon-top@6510000 {
			compatible = "allwinner,sun50i-h616-tcon-top\0allwinner,sun50i-h6-tcon-top";
			reg = <0x6510000 0x1000>;
			clocks = <0x02 0x76 0x02 0x77>;
			clock-names = "bus\0tcon-tv0";
			clock-output-names = "tcon-top-tv0";
			resets = <0x02 0x35>;
			#clock-cells = <0x01>;
			phandle = <0x3d>;

			ports {
				#address-cells = <0x01>;
				#size-cells = <0x00>;

				port@0 {
					#address-cells = <0x01>;
					#size-cells = <0x00>;
					reg = <0x00>;
					phandle = <0x98>;

					endpoint@0 {
						reg = <0x00>;
						remote-endpoint = <0x32>;
						phandle = <0x0f>;
					};
				};

				port@1 {
					#address-cells = <0x01>;
					#size-cells = <0x00>;
					reg = <0x01>;
					phandle = <0x99>;

					endpoint@0 {
						reg = <0x00>;
						remote-endpoint = <0x33>;
						phandle = <0x3a>;
					};

					endpoint@2 {
						reg = <0x02>;
						remote-endpoint = <0x34>;
						phandle = <0x3e>;
					};
				};

				port@2 {
					#address-cells = <0x01>;
					#size-cells = <0x00>;
					reg = <0x02>;
					phandle = <0x9a>;

					endpoint@1 {
						reg = <0x01>;
						remote-endpoint = <0x35>;
						phandle = <0x10>;
					};
				};

				port@3 {
					#address-cells = <0x01>;
					#size-cells = <0x00>;
					reg = <0x03>;
					phandle = <0x9b>;

					endpoint@0 {
						reg = <0x00>;
						remote-endpoint = <0x36>;
						phandle = <0x3b>;
					};

					endpoint@2 {
						reg = <0x02>;
						remote-endpoint = <0x37>;
						phandle = <0x3f>;
					};
				};

				port@4 {
					#address-cells = <0x01>;
					#size-cells = <0x00>;
					reg = <0x04>;
					phandle = <0x9c>;

					endpoint@0 {
						reg = <0x00>;
						remote-endpoint = <0x38>;
						phandle = <0x40>;
					};
				};

				port@5 {
					reg = <0x05>;
					phandle = <0x9d>;

					endpoint {
						remote-endpoint = <0x39>;
						phandle = <0x30>;
					};
				};
			};
		};

		lcd-controller@6511000 {
			compatible = "allwinner,sun50i-h616-tcon-lcd\0allwinner,sun8i-r40-tcon-lcd";
			reg = <0x6511000 0x1000>;
			interrupts = <0x00 0x40 0x04>;
			clocks = <0x02 0x83 0x02 0x82>;
			clock-names = "ahb\0tcon-ch0";
			clock-output-names = "tcon-data-clock";
			#clock-cells = <0x00>;
			resets = <0x02 0x3d 0x02 0x3f>;
			reset-names = "lcd\0lvds";
			status = "okay";
			phandle = <0x9e>;

			ports {
				#address-cells = <0x01>;
				#size-cells = <0x00>;

				port@0 {
					#address-cells = <0x01>;
					#size-cells = <0x00>;
					reg = <0x00>;
					phandle = <0x9f>;

					endpoint@0 {
						reg = <0x00>;
						remote-endpoint = <0x3a>;
						phandle = <0x33>;
					};

					endpoint@1 {
						reg = <0x01>;
						remote-endpoint = <0x3b>;
						phandle = <0x36>;
					};
				};

				port@1 {
					reg = <0x01>;
					#address-cells = <0x01>;
					#size-cells = <0x00>;
					phandle = <0xa0>;

					endpoint@0 {
						reg = <0x00>;
						remote-endpoint = <0x3c>;
						phandle = <0x54>;
					};
				};
			};
		};

		lcd-controller@6515000 {
			compatible = "allwinner,sun50i-h616-tcon-tv";
			reg = <0x6515000 0x1000>;
			interrupts = <0x00 0x42 0x04>;
			clocks = <0x02 0x79 0x3d 0x00>;
			clock-names = "ahb\0tcon-ch1";
			resets = <0x02 0x36>;
			reset-names = "lcd";
			phandle = <0xa1>;

			ports {
				#address-cells = <0x01>;
				#size-cells = <0x00>;

				port@0 {
					#address-cells = <0x01>;
					#size-cells = <0x00>;
					reg = <0x00>;
					phandle = <0xa2>;

					endpoint@0 {
						reg = <0x00>;
						remote-endpoint = <0x3e>;
						phandle = <0x34>;
					};

					endpoint@1 {
						reg = <0x01>;
						remote-endpoint = <0x3f>;
						phandle = <0x37>;
					};
				};

				port@1 {
					#address-cells = <0x01>;
					#size-cells = <0x00>;
					reg = <0x01>;
					phandle = <0xa3>;

					endpoint@1 {
						reg = <0x01>;
						remote-endpoint = <0x40>;
						phandle = <0x38>;
					};
				};
			};
		};

		rtc@7000000 {
			compatible = "allwinner,sun50i-h616-rtc";
			reg = <0x7000000 0x400>;
			interrupts = <0x00 0x68 0x04>;
			clocks = <0x41 0x0e 0x15 0x02 0x80>;
			clock-names = "bus\0hosc\0pll-32k";
			#clock-cells = <0x01>;
			phandle = <0x14>;
		};

		clock@7010000 {
			compatible = "allwinner,sun50i-h616-r-ccu";
			reg = <0x7010000 0x210>;
			clocks = <0x15 0x14 0x00 0x14 0x02 0x02 0x04>;
			clock-names = "hosc\0losc\0iosc\0pll-periph";
			#clock-cells = <0x01>;
			#reset-cells = <0x01>;
			phandle = <0x41>;
		};

		power-controller@7010250 {
			compatible = "allwinner,sun50i-h616-prcm-ppu";
			reg = <0x7010250 0x10>;
			#power-domain-cells = <0x01>;
			phandle = <0x11>;
		};

		interrupt-controller@7010320 {
			compatible = "allwinner,sun50i-h616-nmi\0allwinner,sun9i-a80-nmi";
			reg = <0x7010320 0x0c>;
			interrupt-controller;
			#interrupt-cells = <0x02>;
			interrupts = <0x00 0x67 0x04>;
			phandle = <0x44>;
		};

		pinctrl@7022000 {
			compatible = "allwinner,sun50i-h616-r-pinctrl";
			reg = <0x7022000 0x400>;
			clocks = <0x41 0x02 0x15 0x14 0x00>;
			clock-names = "apb\0hosc\0losc";
			gpio-controller;
			#gpio-cells = <0x03>;
			phandle = <0xa4>;

			r-i2c-pins {
				pins = "PL0\0PL1";
				function = "s_i2c";
				phandle = <0x43>;
			};

			r-rsb-pins {
				pins = "PL0\0PL1";
				function = "s_rsb";
				phandle = <0x47>;
			};
		};

		ir@7040000 {
			compatible = "allwinner,sun50i-h616-ir\0allwinner,sun6i-a31-ir";
			reg = <0x7040000 0x400>;
			interrupts = <0x00 0x6a 0x04>;
			clocks = <0x41 0x09 0x41 0x0b>;
			clock-names = "apb\0ir";
			resets = <0x41 0x05>;
			pinctrl-names = "default";
			pinctrl-0 = <0x42>;
			status = "disabled";
			phandle = <0xa5>;
		};

		i2c@7081400 {
			compatible = "allwinner,sun50i-h616-i2c\0allwinner,sun8i-v536-i2c\0allwinner,sun6i-a31-i2c";
			reg = <0x7081400 0x400>;
			interrupts = <0x00 0x69 0x04>;
			clocks = <0x41 0x08>;
			dmas = <0x18 0x30 0x18 0x30>;
			dma-names = "rx\0tx";
			resets = <0x41 0x04>;
			pinctrl-names = "default";
			pinctrl-0 = <0x43>;
			status = "okay";
			#address-cells = <0x01>;
			#size-cells = <0x00>;
			phandle = <0xa6>;

			pmic@34 {
				compatible = "x-powers,axp717";
				reg = <0x34>;
				interrupt-controller;
				#interrupt-cells = <0x01>;
				interrupt-parent = <0x44>;
				interrupts = <0x00 0x08>;
				vin1-supply = <0x45>;
				vin2-supply = <0x45>;
				vin3-supply = <0x45>;
				vin4-supply = <0x45>;
				phandle = <0xa7>;

				adc {
					compatible = "x-powers,axp717-adc";
					#io-channel-cells = <0x01>;
					phandle = <0xa8>;
				};

				battery-power {
					compatible = "x-powers,axp717-battery-power-supply";
					monitored-battery = <0x46>;
					x-powers,no-thermistor;
					phandle = <0xa9>;
				};

				regulators {

					dcdc1 {
						regulator-always-on;
						regulator-min-microvolt = <0xdbba0>;
						regulator-max-microvolt = <0x11b340>;
						regulator-name = "vdd-cpu";
						phandle = <0x05>;
					};

					dcdc2 {
						regulator-always-on;
						regulator-min-microvolt = <0xdbba0>;
						regulator-max-microvolt = <0xea600>;
						regulator-name = "vdd-gpu-sys";
						phandle = <0x12>;
					};

					dcdc3 {
						regulator-always-on;
						regulator-min-microvolt = <0x10c8e0>;
						regulator-max-microvolt = <0x10c8e0>;
						regulator-name = "vdd-dram";
						phandle = <0xaa>;
					};

					aldo1 {
						phandle = <0xab>;
					};

					aldo2 {
						phandle = <0xac>;
					};

					aldo3 {
						phandle = <0xad>;
					};

					aldo4 {
						regulator-min-microvolt = <0x1b7740>;
						regulator-max-microvolt = <0x1b7740>;
						regulator-name = "avcc";
						phandle = <0x17>;
					};

					bldo1 {
						phandle = <0xae>;
					};

					bldo2 {
						regulator-always-on;
						regulator-min-microvolt = <0x1b7740>;
						regulator-max-microvolt = <0x1b7740>;
						regulator-name = "vcc-pll";
						phandle = <0xaf>;
					};

					bldo3 {
						phandle = <0xb0>;
					};

					bldo4 {
						phandle = <0xb1>;
					};

					cldo1 {
						regulator-min-microvolt = <0x325aa0>;
						regulator-max-microvolt = <0x325aa0>;
						regulator-name = "vcc-spkr-amp";
						phandle = <0x27>;
					};

					cldo2 {
						phandle = <0xb2>;
					};

					cldo3 {
						regulator-always-on;
						regulator-min-microvolt = <0x325aa0>;
						regulator-max-microvolt = <0x325aa0>;
						regulator-name = "vcc-io";
						phandle = <0x16>;
					};

					cldo4 {
						regulator-min-microvolt = <0x325aa0>;
						regulator-max-microvolt = <0x325aa0>;
						regulator-name = "vcc-wifi";
						phandle = <0x1c>;
					};

					boost {
						regulator-min-microvolt = <0x4c4b40>;
						regulator-max-microvolt = <0x4f5880>;
						regulator-name = "boost";
						phandle = <0x55>;
					};

					cpusldo {
						regulator-always-on;
						regulator-boot-on;
						regulator-min-microvolt = <0xdbba0>;
						regulator-max-microvolt = <0xdbba0>;
						phandle = <0xb3>;
					};
				};

				usb-power {
					compatible = "x-powers,axp717-usb-power-supply";
					input-current-limit-microamp = <0x16e360>;
					phandle = <0x2d>;
				};
			};

			rtc@51 {
				compatible = "nxp,pcf8563";
				reg = <0x51>;
				#clock-cells = <0x00>;
				phandle = <0xb4>;
			};
		};

		rsb@7083000 {
			compatible = "allwinner,sun50i-h616-rsb\0allwinner,sun8i-a23-rsb";
			reg = <0x7083000 0x400>;
			interrupts = <0x00 0x6d 0x04>;
			clocks = <0x41 0x0d>;
			clock-frequency = <0x2dc6c0>;
			resets = <0x41 0x07>;
			pinctrl-names = "default";
			pinctrl-0 = <0x47>;
			status = "disabled";
			#address-cells = <0x01>;
			#size-cells = <0x00>;
			phandle = <0xb5>;
		};
	};

	thermal-zones {

		cpu-thermal {
			polling-delay-passive = <0x1f4>;
			polling-delay = <0x3e8>;
			thermal-sensors = <0x48 0x02>;
			sustainable-power = <0x3e8>;

			trips {

				cpu-trip-0 {
					temperature = <0xea60>;
					type = "passive";
					hysteresis = <0x00>;
					phandle = <0xb6>;
				};

				cpu-trip-1 {
					temperature = <0x11170>;
					type = "passive";
					hysteresis = <0x00>;
					phandle = <0xb7>;
				};

				cpu-trip-2 {
					temperature = <0x1adb0>;
					type = "critical";
					hysteresis = <0x00>;
					phandle = <0xb8>;
				};
			};
		};

		gpu-thermal {
			polling-delay-passive = <0x1f4>;
			polling-delay = <0x3e8>;
			thermal-sensors = <0x48 0x00>;
			sustainable-power = <0x44c>;

			trips {

				gpu-trip-0 {
					temperature = <0x1adb0>;
					type = "critical";
					hysteresis = <0x00>;
					phandle = <0xb9>;
				};
			};
		};

		ve-thermal {
			polling-delay-passive = <0x00>;
			polling-delay = <0x00>;
			thermal-sensors = <0x48 0x01>;

			trips {

				ve-trip-0 {
					temperature = <0x1adb0>;
					type = "critical";
					hysteresis = <0x00>;
					phandle = <0xba>;
				};
			};
		};

		ddr-thermal {
			polling-delay-passive = <0x00>;
			polling-delay = <0x00>;
			thermal-sensors = <0x48 0x03>;

			trips {

				ddr-trip-0 {
					temperature = <0x1adb0>;
					type = "critical";
					hysteresis = <0x00>;
					phandle = <0xbb>;
				};
			};
		};
	};

	opp-table-cpu {
		compatible = "allwinner,sun50i-h616-operating-points";
		nvmem-cells = <0x49>;
		opp-shared;
		phandle = <0x04>;

		opp-480000000 {
			opp-hz = <0x00 0x1c9c3800>;
			opp-microvolt = <0xdbba0>;
			clock-latency-ns = <0x3b9b0>;
			opp-supported-hw = <0x3f>;
			opp-suspend;
		};

		opp-600000000 {
			opp-hz = <0x00 0x23c34600>;
			opp-microvolt = <0xdbba0>;
			clock-latency-ns = <0x3b9b0>;
			opp-supported-hw = <0x12>;
		};

		opp-720000000 {
			opp-hz = <0x00 0x2aea5400>;
			opp-microvolt = <0xdbba0>;
			clock-latency-ns = <0x3b9b0>;
			opp-supported-hw = <0x2d>;
		};

		opp-792000000 {
			opp-hz = <0x00 0x2f34f600>;
			opp-microvolt-speed1 = <0xdbba0>;
			opp-microvolt-speed4 = <0xe57e0>;
			clock-latency-ns = <0x3b9b0>;
			opp-supported-hw = <0x12>;
		};

		opp-936000000 {
			opp-hz = <0x00 0x37ca3a00>;
			opp-microvolt = <0xdbba0>;
			clock-latency-ns = <0x3b9b0>;
			opp-supported-hw = <0x0d>;
		};

		opp-1008000000 {
			opp-hz = <0x00 0x3c14dc00>;
			opp-microvolt-speed0 = <0xe7ef0>;
			opp-microvolt-speed1 = <0xe57e0>;
			opp-microvolt-speed2 = <0xe7ef0>;
			opp-microvolt-speed3 = <0xe7ef0>;
			opp-microvolt-speed4 = <0xf9060>;
			opp-microvolt-speed5 = <0xdbba0>;
			clock-latency-ns = <0x3b9b0>;
			opp-supported-hw = <0x3f>;
		};

		opp-1104000000 {
			opp-hz = <0x00 0x41cdb400>;
			opp-microvolt-speed0 = <0xf4240>;
			opp-microvolt-speed2 = <0xf4240>;
			opp-microvolt-speed3 = <0xf4240>;
			opp-microvolt-speed5 = <0xe7ef0>;
			clock-latency-ns = <0x3b9b0>;
			opp-supported-hw = <0x2d>;
		};

		opp-1200000000 {
			opp-hz = <0x00 0x47868c00>;
			opp-microvolt-speed0 = <0x100590>;
			opp-microvolt-speed1 = <0xf9060>;
			opp-microvolt-speed2 = <0x100590>;
			opp-microvolt-speed3 = <0x100590>;
			opp-microvolt-speed4 = <0x10c8e0>;
			opp-microvolt-speed5 = <0xf9060>;
			clock-latency-ns = <0x3b9b0>;
			opp-supported-hw = <0x3f>;
		};

		opp-1320000000 {
			opp-hz = <0x00 0x4ead9a00>;
			opp-microvolt = <0x10c8e0>;
			clock-latency-ns = <0x3b9b0>;
			opp-supported-hw = <0x3d>;
		};

		opp-1416000000 {
			opp-hz = <0x00 0x54667200>;
			opp-microvolt = <0x10c8e0>;
			clock-latency-ns = <0x3b9b0>;
			opp-supported-hw = <0x2d>;
		};

		opp-1512000000 {
			opp-hz = <0x00 0x5a1f4a00>;
			opp-microvolt-speed1 = <0x10c8e0>;
			opp-microvolt-speed3 = <0x10c8e0>;
			opp-microvolt-speed5 = <0x11b340>;
			clock-latency-ns = <0x3b9b0>;
			opp-supported-hw = <0x2a>;
			turbo-mode;
		};
	};

	aliases {
		mmc0 = "/soc/mmc@4020000";
		mmc1 = "/soc/mmc@4022000";
		mmc2 = "/soc/mmc@4021000";
		serial0 = "/soc/serial@5000000";
		serial1 = "/soc/serial@5001400";
		rtc0 = "/soc/i2c@7081400/rtc@51";
		rtc1 = "/soc/rtc@7000000";
	};

	backlight {
		compatible = "pwm-backlight";
		pwms = <0x4a 0x00 0x9c40 0x00>;
		pinctrl-0 = <0x4b>;
		pinctrl-names = "default";
		phandle = <0x50>;
	};

	battery {
		compatible = "simple-battery";
		constant-charge-current-max-microamp = <0xfa000>;
		voltage-max-design-microvolt = <0x401640>;
		phandle = <0x46>;
	};

	chosen {
		stdout-path = "serial0:115200n8";
	};

	connector {
		compatible = "hdmi-connector";
		type = "d";

		port {

			endpoint {
				remote-endpoint = <0x4c>;
				phandle = <0x31>;
			};
		};
	};

	rocknix-singleadc-joypad {
		compatible = "rocknix-singleadc-joypad";
		hw_info = <0x01>;
		joypad-name = "H700 Gamepad";
		joypad-product = <0x14df>;
		joypad-revision = <0x100>;
		joypad-vendor = <0x484b>;
		status = "okay";
		pwms = <0x4a 0x02 0xf4240 0x00>;
		pwm-names = "enable";
		rumble-boost-weak = <0x00>;
		rumble-boost-strong = <0x00>;
		pinctrl-names = "default";
		pinctrl-0 = <0x4d 0x4e>;
		io-channel-names = "amux_adc";
		io-channels = <0x4f 0x00>;
		amux-count = <0x04>;
		amux-channel-mapping = <0x00 0x02 0x01 0x03>;
		amux-a-gpios = <0x1a 0x08 0x01 0x01>;
		amux-b-gpios = <0x1a 0x08 0x02 0x01>;
		button-adc-scale = <0x02>;
		button-adc-deadzone = <0x80>;
		button-adc-fuzz = <0x20>;
		button-adc-flat = <0x20>;
		abs_x-p-tuning = <0x46>;
		abs_x-n-tuning = <0x46>;
		invert-absx;
		abs_y-p-tuning = <0x46>;
		abs_y-n-tuning = <0x46>;
		invert-absy;
		abs_rx-p-tuning = <0x46>;
		abs_rx-n-tuning = <0x46>;
		abs_ry-p-tuning = <0x46>;
		abs_ry-n-tuning = <0x46>;
		poll-interval = <0x0a>;
		invert-absrx;
		invert-absry;
		phandle = <0xbc>;

		sw1 {
			gpios = <0x1a 0x00 0x06 0x01>;
			label = "GPIO DPAD-UP";
			linux,code = <0x220>;
		};

		sw2 {
			gpios = <0x1a 0x04 0x00 0x01>;
			label = "GPIO DPAD-DOWN";
			linux,code = <0x221>;
		};

		sw3 {
			gpios = <0x1a 0x00 0x08 0x01>;
			label = "GPIO DPAD-LEFT";
			linux,code = <0x222>;
		};

		sw4 {
			gpios = <0x1a 0x00 0x09 0x01>;
			label = "GPIO DPAD-RIGHT";
			linux,code = <0x223>;
		};

		sw5 {
			gpios = <0x1a 0x00 0x00 0x01>;
			label = "GPIO BTN-A";
			linux,code = <0x131>;
		};

		sw6 {
			gpios = <0x1a 0x00 0x01 0x01>;
			label = "GPIO BTN-B";
			linux,code = <0x130>;
		};

		sw7 {
			gpios = <0x1a 0x00 0x03 0x01>;
			label = "GPIO BTN-X";
			linux,code = <0x133>;
		};

		sw8 {
			gpios = <0x1a 0x00 0x02 0x01>;
			label = "GPIO BTN-Y";
			linux,code = <0x134>;
		};

		sw9 {
			gpios = <0x1a 0x00 0x05 0x01>;
			label = "BTN_SELECT";
			linux,code = <0x13a>;
		};

		sw10 {
			gpios = <0x1a 0x00 0x04 0x01>;
			label = "BTN_START";
			linux,code = <0x13b>;
		};

		sw11 {
			gpios = <0x1a 0x04 0x03 0x01>;
			label = "GPIO BTN_F";
			linux,code = <0x13c>;
		};

		sw12 {
			gpios = <0x1a 0x04 0x08 0x01>;
			label = "BTN_THUMBL";
			linux,code = <0x13d>;
		};

		sw13 {
			gpios = <0x1a 0x04 0x09 0x01>;
			label = "BTN_THUMBR";
			linux,code = <0x13e>;
		};

		sw14 {
			gpios = <0x1a 0x00 0x0c 0x01>;
			label = "GPIO BTN_TR";
			linux,code = <0x137>;
		};

		sw15 {
			gpios = <0x1a 0x00 0x07 0x01>;
			label = "GPIO BTN_TR2";
			linux,code = <0x139>;
		};

		sw16 {
			gpios = <0x1a 0x00 0x0a 0x01>;
			label = "GPIO BTN_TL";
			linux,code = <0x136>;
		};

		sw17 {
			gpios = <0x1a 0x00 0x0b 0x01>;
			label = "GPIO BTN_TL2";
			linux,code = <0x138>;
		};
	};

	gpio-keys-volume {
		compatible = "gpio-keys";
		autorepeat;

		button-vol-up {
			label = "Key Volume Up";
			gpios = <0x1a 0x04 0x01 0x01>;
			linux,input-type = <0x01>;
			linux,code = <0x73>;
		};

		button-vol-down {
			label = "Key Volume Down";
			gpios = <0x1a 0x04 0x02 0x01>;
			linux,input-type = <0x01>;
			linux,code = <0x72>;
		};
	};

	leds {
		compatible = "gpio-leds";
		phandle = <0xbd>;

		led-0 {
			function = "power";
			color = <0x02>;
			gpios = <0x1a 0x08 0x0c 0x00>;
			default-state = "on";
		};

		led-1 {
			function = "status";
			color = <0x01>;
			gpios = <0x1a 0x08 0x0b 0x00>;
		};
	};

	regulator-vcc5v {
		compatible = "regulator-fixed";
		regulator-name = "vcc-5v";
		regulator-min-microvolt = <0x4c4b40>;
		regulator-max-microvolt = <0x4c4b40>;
		phandle = <0x45>;
	};

	regulator-gpio-lcd-vdd {
		compatible = "regulator-fixed";
		regulator-min-microvolt = <0x325aa0>;
		regulator-max-microvolt = <0x325aa0>;
		regulator-name = "vdd-lcd";
		gpio = <0x1a 0x08 0x0f 0x00>;
		enable-active-high;
		phandle = <0x51>;
	};

	spi {
		compatible = "spi-gpio";
		#address-cells = <0x01>;
		#size-cells = <0x00>;
		sck-gpios = <0x1a 0x08 0x09 0x00>;
		mosi-gpios = <0x1a 0x08 0x0a 0x00>;
		cs-gpios = <0x1a 0x08 0x08 0x00>;
		num-chipselects = <0x01>;
		phandle = <0xbe>;

		panel@0 {
			compatible = "anbernic,rg34xx-sp-panel\0panel-mipi-dpi-spi";
			reg = <0x00>;
			spi-max-frequency = <0x2faf08>;
			spi-3wire;
			reset-gpios = <0x1a 0x08 0x0e 0x01>;
			backlight = <0x50>;
			power-supply = <0x51>;
			pinctrl-0 = <0x52>;
			pinctrl-1 = <0x53>;
			pinctrl-names = "default\0sleep";
			phandle = <0xbf>;

			port {

				endpoint {
					remote-endpoint = <0x54>;
					phandle = <0x3c>;
				};
			};
		};
	};

	opp-table-1 {
		compatible = "operating-points-v2";
		phandle = <0x13>;

		opp-420000000 {
			opp-hz = <0x00 0x1908b100>;
			opp-microvolt = <0xdbba0>;
		};

		opp-456000000 {
			opp-hz = <0x00 0x1b2e0200>;
			opp-microvolt = <0xdbba0>;
		};

		opp-504000000 {
			opp-hz = <0x00 0x1e0a6e00>;
			opp-microvolt = <0xdbba0>;
		};

		opp-552000000 {
			opp-hz = <0x00 0x20e6da00>;
			opp-microvolt = <0xdbba0>;
		};

		opp-600000000 {
			opp-hz = <0x00 0x23c34600>;
			opp-microvolt = <0xdbba0>;
		};

		opp-648000000 {
			opp-hz = <0x00 0x269fb200>;
			opp-microvolt = <0xea600>;
		};
	};

	regulator-vcc3v3-mmc2 {
		compatible = "regulator-fixed";
		enable-active-high;
		gpio = <0x1a 0x04 0x04 0x00>;
		regulator-min-microvolt = <0x325aa0>;
		regulator-max-microvolt = <0x325aa0>;
		regulator-name = "vcc3v3-mmc2";
		regulator-always-on;
		phandle = <0x1f>;
	};

	regulator-usb0-vbus {
		compatible = "regulator-fixed";
		enable-active-high;
		gpio = <0x1a 0x08 0x10 0x00>;
		regulator-min-microvolt = <0x4c4b40>;
		regulator-max-microvolt = <0x4c4b40>;
		regulator-name = "usb0-vbus";
		vin-supply = <0x55>;
		phandle = <0x2e>;
	};

	pwrseq {
		compatible = "mmc-pwrseq-simple";
		clocks = <0x14 0x01>;
		clock-names = "ext_clock";
		pinctrl-0 = <0x56>;
		pinctrl-names = "default";
		post-power-on-delay-ms = <0xc8>;
		reset-gpios = <0x1a 0x06 0x12 0x01>;
		phandle = <0x1d>;
	};

	gpio-keys-lid {
		compatible = "gpio-keys";

		lid-switch {
			label = "Lid Switch";
			gpios = <0x1a 0x04 0x07 0x01>;
			linux,can-disable;
			linux,code = <0x00>;
			linux,input-type = <0x05>;
			wakeup-event-action = <0x02>;
			wakeup-source;
		};
	};

	__symbols__ {
		cpu0 = "/cpus/cpu@0";
		cpu1 = "/cpus/cpu@1";
		cpu2 = "/cpus/cpu@2";
		cpu3 = "/cpus/cpu@3";
		l2_cache = "/cpus/l2-cache";
		de = "/display-engine";
		osc24M = "/osc24M-clk";
		display_clocks = "/soc/bus@1000000/clock@8000";
		planes = "/soc/bus@1000000/planes@100000";
		mixer0 = "/soc/bus@1000000/mixer@280000";
		mixer0_out = "/soc/bus@1000000/mixer@280000/ports/port@1";
		mixer0_out_tcon_top_mixer0 = "/soc/bus@1000000/mixer@280000/ports/port@1/endpoint";
		mixer1 = "/soc/bus@1000000/mixer@2a0000";
		mixer1_out = "/soc/bus@1000000/mixer@2a0000/ports/port@1";
		mixer1_out_tcon_top_mixer1 = "/soc/bus@1000000/mixer@2a0000/ports/port@1/endpoint";
		gpu = "/soc/gpu@1800000";
		crypto = "/soc/crypto@1904000";
		syscon = "/soc/syscon@3000000";
		sram_c = "/soc/syscon@3000000/sram@28000/sram-section@0";
		ve_sram = "/soc/syscon@3000000/sram@1a00000/sram-section@0";
		ccu = "/soc/clock@3001000";
		dma = "/soc/dma-controller@3002000";
		sid = "/soc/efuse@3006000";
		ths_calibration = "/soc/efuse@3006000/thermal-sensor-calibration@14";
		cpu_speed_grade = "/soc/efuse@3006000/cpu-speed-grade@0";
		timer0 = "/soc/timer@3009000";
		watchdog = "/soc/watchdog@30090a0";
		pwm = "/soc/pwm@300a000";
		pio = "/soc/pinctrl@300b000";
		ext_rgmii_pins = "/soc/pinctrl@300b000/rgmii-pins";
		i2c0_pins = "/soc/pinctrl@300b000/i2c0-pins";
		i2c3_ph_pins = "/soc/pinctrl@300b000/i2c3-ph-pins";
		ir_rx_pin = "/soc/pinctrl@300b000/ir-rx-pin";
		lcd0_rgb888_pins = "/soc/pinctrl@300b000/lcd0-rgb888-pins";
		lcd0_suspend_pins = "/soc/pinctrl@300b000/lcd0-suspend-pins";
		lvds0_pins = "/soc/pinctrl@300b000/lvds0-pins";
		lvds1_pins = "/soc/pinctrl@300b000/lvds1-pins";
		mmc0_pins = "/soc/pinctrl@300b000/mmc0-pins";
		mmc1_pins = "/soc/pinctrl@300b000/mmc1-pins";
		mmc2_pins = "/soc/pinctrl@300b000/mmc2-pins";
		nand_pins = "/soc/pinctrl@300b000/nand-pins";
		nand_cs0_pin = "/soc/pinctrl@300b000/nand-cs0-pin";
		nand_cs1_pin = "/soc/pinctrl@300b000/nand-cs1-pin";
		nand_rb0_pin = "/soc/pinctrl@300b000/nand-rb0-pin";
		nand_rb1_pin = "/soc/pinctrl@300b000/nand-rb1-pin";
		lcd_backlight_pin = "/soc/pinctrl@300b000/pwm0-pin";
		pwm0_pin = "/soc/pinctrl@300b000/pwm0-pin";
		pwm1_pin = "/soc/pinctrl@300b000/pwm1-pin";
		pwm2_pin = "/soc/pinctrl@300b000/pwm2-pin";
		pwm3_pin = "/soc/pinctrl@300b000/pwm3-pin";
		pwm4_pin = "/soc/pinctrl@300b000/pwm4-pin";
		pwm5_pin = "/soc/pinctrl@300b000/pwm5-pin";
		spi0_pins = "/soc/pinctrl@300b000/spi0-pins";
		spi0_cs0_pin = "/soc/pinctrl@300b000/spi0-cs0-pin";
		spi1_pins = "/soc/pinctrl@300b000/spi1-pins";
		spi1_cs0_pin = "/soc/pinctrl@300b000/spi1-cs0-pin";
		spdif_tx_pin = "/soc/pinctrl@300b000/spdif-tx-pin";
		uart0_ph_pins = "/soc/pinctrl@300b000/uart0-ph-pins";
		uart1_pins = "/soc/pinctrl@300b000/uart1-pins";
		uart1_rts_cts_pins = "/soc/pinctrl@300b000/uart1-rts-cts-pins";
		x32clk_fanout_pin = "/soc/pinctrl@300b000/x32clk-fanout-pin";
		joy_mux_pin = "/soc/pinctrl@300b000/joy-mux-pin";
		uart5_ph_pins = "/soc/pinctrl@300b000/uart5-ph-pins";
		gic = "/soc/interrupt-controller@3021000";
		iommu = "/soc/iommu@30f0000";
		nfc = "/soc/nand-controller@4011000";
		mmc0 = "/soc/mmc@4020000";
		mmc1 = "/soc/mmc@4021000";
		sdio_wifi = "/soc/mmc@4021000/wifi@1";
		mmc2 = "/soc/mmc@4022000";
		uart0 = "/soc/serial@5000000";
		uart1 = "/soc/serial@5000400";
		uart2 = "/soc/serial@5000800";
		uart3 = "/soc/serial@5000c00";
		uart4 = "/soc/serial@5001000";
		uart5 = "/soc/serial@5001400";
		i2c0 = "/soc/i2c@5002000";
		i2c1 = "/soc/i2c@5002400";
		i2c2 = "/soc/i2c@5002800";
		i2c3 = "/soc/i2c@5002c00";
		i2c4 = "/soc/i2c@5003000";
		spi0 = "/soc/spi@5010000";
		spi1 = "/soc/spi@5011000";
		emac0 = "/soc/ethernet@5020000";
		mdio0 = "/soc/ethernet@5020000/mdio";
		gpadc = "/soc/adc@5070000";
		ths = "/soc/thermal-sensor@5070400";
		lradc = "/soc/lradc@5070800";
		spdif = "/soc/spdif@5093000";
		codec = "/soc/codec@5096000";
		ahub_dam_plat = "/soc/ahub_dam_plat@5097000";
		ahub_dam_mach = "/soc/ahub_dam_mach";
		ahub1_plat = "/soc/ahub1_plat";
		ahub1_mach_hdmi = "/soc/ahub1_mach_hdmi";
		ahub1_cpu = "/soc/ahub1_mach_hdmi/soundcard-mach,cpu";
		ahub1_codec = "/soc/ahub1_mach_hdmi/soundcard-mach,codec";
		usbotg = "/soc/usb@5100000";
		usbphy = "/soc/phy@5100400";
		ehci0 = "/soc/usb@5101000";
		ohci0 = "/soc/usb@5101400";
		ehci1 = "/soc/usb@5200000";
		ohci1 = "/soc/usb@5200400";
		ehci2 = "/soc/usb@5310000";
		ohci2 = "/soc/usb@5310400";
		ehci3 = "/soc/usb@5311000";
		ohci3 = "/soc/usb@5311400";
		hdmi = "/soc/hdmi@6000000";
		hdmi_in = "/soc/hdmi@6000000/ports/port@0";
		hdmi_in_tcon_top = "/soc/hdmi@6000000/ports/port@0/endpoint";
		hdmi_out = "/soc/hdmi@6000000/ports/port@1";
		hdmi_out_con = "/soc/hdmi@6000000/ports/port@1/endpoint";
		hdmi_phy = "/soc/hdmi-phy@6010000";
		tcon_top = "/soc/tcon-top@6510000";
		tcon_top_mixer0_in = "/soc/tcon-top@6510000/ports/port@0";
		tcon_top_mixer0_in_mixer0 = "/soc/tcon-top@6510000/ports/port@0/endpoint@0";
		tcon_top_mixer0_out = "/soc/tcon-top@6510000/ports/port@1";
		tcon_top_mixer0_out_tcon_lcd0 = "/soc/tcon-top@6510000/ports/port@1/endpoint@0";
		tcon_top_mixer0_out_tcon_tv0 = "/soc/tcon-top@6510000/ports/port@1/endpoint@2";
		tcon_top_mixer1_in = "/soc/tcon-top@6510000/ports/port@2";
		tcon_top_mixer1_in_mixer1 = "/soc/tcon-top@6510000/ports/port@2/endpoint@1";
		tcon_top_mixer1_out = "/soc/tcon-top@6510000/ports/port@3";
		tcon_top_mixer1_out_tcon_lcd0 = "/soc/tcon-top@6510000/ports/port@3/endpoint@0";
		tcon_top_mixer1_out_tcon_tv0 = "/soc/tcon-top@6510000/ports/port@3/endpoint@2";
		tcon_top_hdmi_in = "/soc/tcon-top@6510000/ports/port@4";
		tcon_top_hdmi_in_tcon_tv0 = "/soc/tcon-top@6510000/ports/port@4/endpoint@0";
		tcon_top_hdmi_out = "/soc/tcon-top@6510000/ports/port@5";
		tcon_top_hdmi_out_hdmi = "/soc/tcon-top@6510000/ports/port@5/endpoint";
		tcon_lcd0 = "/soc/lcd-controller@6511000";
		tcon_lcd0_in = "/soc/lcd-controller@6511000/ports/port@0";
		tcon_lcd0_in_tcon_top_mixer0 = "/soc/lcd-controller@6511000/ports/port@0/endpoint@0";
		tcon_lcd0_in_tcon_top_mixer1 = "/soc/lcd-controller@6511000/ports/port@0/endpoint@1";
		tcon_lcd0_out = "/soc/lcd-controller@6511000/ports/port@1";
		tcon_lcd0_out_lcd = "/soc/lcd-controller@6511000/ports/port@1/endpoint@0";
		tcon_tv0 = "/soc/lcd-controller@6515000";
		tcon_tv0_in = "/soc/lcd-controller@6515000/ports/port@0";
		tcon_tv0_in_tcon_top_mixer0 = "/soc/lcd-controller@6515000/ports/port@0/endpoint@0";
		tcon_tv0_in_tcon_top_mixer1 = "/soc/lcd-controller@6515000/ports/port@0/endpoint@1";
		tcon_tv0_out = "/soc/lcd-controller@6515000/ports/port@1";
		tcon_tv0_out_tcon_top = "/soc/lcd-controller@6515000/ports/port@1/endpoint@1";
		rtc = "/soc/rtc@7000000";
		r_ccu = "/soc/clock@7010000";
		prcm_ppu = "/soc/power-controller@7010250";
		nmi_intc = "/soc/interrupt-controller@7010320";
		r_pio = "/soc/pinctrl@7022000";
		r_i2c_pins = "/soc/pinctrl@7022000/r-i2c-pins";
		r_rsb_pins = "/soc/pinctrl@7022000/r-rsb-pins";
		ir = "/soc/ir@7040000";
		r_i2c = "/soc/i2c@7081400";
		axp717 = "/soc/i2c@7081400/pmic@34";
		axp_adc = "/soc/i2c@7081400/pmic@34/adc";
		battery_power = "/soc/i2c@7081400/pmic@34/battery-power";
		reg_dcdc1 = "/soc/i2c@7081400/pmic@34/regulators/dcdc1";
		reg_dcdc2 = "/soc/i2c@7081400/pmic@34/regulators/dcdc2";
		reg_dcdc3 = "/soc/i2c@7081400/pmic@34/regulators/dcdc3";
		reg_aldo1 = "/soc/i2c@7081400/pmic@34/regulators/aldo1";
		reg_aldo2 = "/soc/i2c@7081400/pmic@34/regulators/aldo2";
		reg_aldo3 = "/soc/i2c@7081400/pmic@34/regulators/aldo3";
		reg_aldo4 = "/soc/i2c@7081400/pmic@34/regulators/aldo4";
		reg_bldo1 = "/soc/i2c@7081400/pmic@34/regulators/bldo1";
		reg_bldo2 = "/soc/i2c@7081400/pmic@34/regulators/bldo2";
		reg_bldo3 = "/soc/i2c@7081400/pmic@34/regulators/bldo3";
		reg_bldo4 = "/soc/i2c@7081400/pmic@34/regulators/bldo4";
		reg_cldo1 = "/soc/i2c@7081400/pmic@34/regulators/cldo1";
		reg_cldo2 = "/soc/i2c@7081400/pmic@34/regulators/cldo2";
		reg_cldo3 = "/soc/i2c@7081400/pmic@34/regulators/cldo3";
		reg_cldo4 = "/soc/i2c@7081400/pmic@34/regulators/cldo4";
		reg_boost = "/soc/i2c@7081400/pmic@34/regulators/boost";
		reg_cpusldo = "/soc/i2c@7081400/pmic@34/regulators/cpusldo";
		usb_power = "/soc/i2c@7081400/pmic@34/usb-power";
		rtc_ext = "/soc/i2c@7081400/rtc@51";
		pcf8563 = "/soc/i2c@7081400/rtc@51";
		r_rsb = "/soc/rsb@7083000";
		cpu_threshold = "/thermal-zones/cpu-thermal/trips/cpu-trip-0";
		cpu_target = "/thermal-zones/cpu-thermal/trips/cpu-trip-1";
		cpu_critical = "/thermal-zones/cpu-thermal/trips/cpu-trip-2";
		gpu_temp_critical = "/thermal-zones/gpu-thermal/trips/gpu-trip-0";
		ve_temp_critical = "/thermal-zones/ve-thermal/trips/ve-trip-0";
		ddr_temp_critical = "/thermal-zones/ddr-thermal/trips/ddr-trip-0";
		cpu_opp_table = "/opp-table-cpu";
		backlight = "/backlight";
		battery = "/battery";
		hdmi_con_in = "/connector/port/endpoint";
		joypad = "/rocknix-singleadc-joypad";
		leds = "/leds";
		reg_vcc5v = "/regulator-vcc5v";
		reg_lcd = "/regulator-gpio-lcd-vdd";
		spi_lcd = "/spi";
		panel = "/spi/panel@0";
		panel_in_rgb = "/spi/panel@0/port/endpoint";
		gpu_opp_table = "/opp-table-1";
		reg_vcc3v3_mmc2 = "/regulator-vcc3v3-mmc2";
		reg_usb0_vbus = "/regulator-usb0-vbus";
		wifi_pwrseq = "/pwrseq";
	};
};
